# CH569 register map
Vendor: WCH Ltd.; File version: 1.0
Registers are 32-bit, read-write, reset 0x0 unless marked. A register's access mark holds for its fields unless they carry their own. Offsets are from the block's base; [hi:lo] are bit positions; {n}, {i} and the like mark numbered series; 'fields as' and 'values as' point back to an identical list.

## USBHS
Base 0x40009000
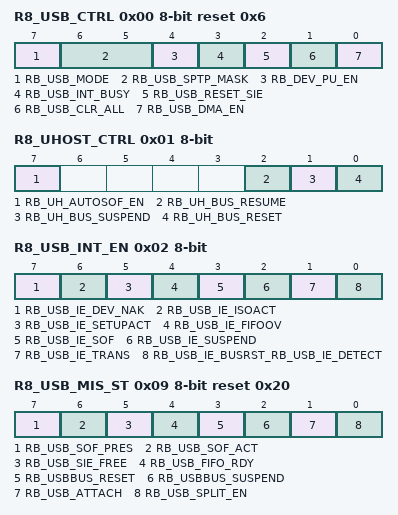
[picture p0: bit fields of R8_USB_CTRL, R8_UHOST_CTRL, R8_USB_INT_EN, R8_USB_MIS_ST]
0x00 R8_USB_CTRL 8-bit reset 0x6 — USB base control
  [7] RB_USB_MODE — enable USB host mode: 0=device mode, 1=host mode
  [6:5] RB_USB_SPTP_MASK — enable USB low speed
  [4] RB_DEV_PU_EN — USB device enable and internal pullup resistance enable
  [3] RB_USB_INT_BUSY — enable automatic responding busy for device mode or automatic pause for host mode during interrupt flag UIF_TRANSFER valid
  [2] RB_USB_RESET_SIE — force reset USB SIE, need software clear
  [1] RB_USB_CLR_ALL — force clear FIFO and count of USB
  [0] RB_USB_DMA_EN — DMA enable and DMA interrupt enable for USB
0x01 R8_UHOST_CTRL 8-bit — USB host control register
  [7] RB_UH_AUTOSOF_EN — Automatically generate sof packet enable control
  [2] RB_UH_BUS_RESUME — USB host suspend state and wake up device
  [1] RB_UH_BUS_SUSPEND — USB host send bus suspend signal
  [0] RB_UH_BUS_RESET — USB host send bus reset signal
0x02 R8_USB_INT_EN 8-bit — USB interrupt enable
  [7] RB_USB_IE_DEV_NAK — enable interrupt for NAK responded for USB device mode
  [6] RB_USB_IE_ISOACT — Synchronous transmission received control token packet interrupt
  [5] RB_USB_IE_SETUPACT — Setup packet end interrupt
  [4] RB_USB_IE_FIFOOV — enable interrupt for FIFO overflow
  [3] RB_USB_IE_SOF — enable interrupt for host SOF timer action for USB host mode
  [2] RB_USB_IE_SUSPEND — enable interrupt for USB suspend or resume event
  [1] RB_USB_IE_TRANS — enable interrupt for USB transfer completion
  [0] RB_USB_IE_BUSRST_RB_USB_IE_DETECT — enable interrupt for USB bus reset event for USB device mode _ enable interrupt for USB device detected event for USB host mode
0x03 R8_USB_DEV_AD 8-bit — USB device address
  [6:0] USB_ADDR_MASK — bit mask for USB device address
0x04 R16_USB_FRAME_NO 16-bit ro — USB frame number register
  [15:0] USB_FRAME_NO — USB frame number
0x06 R8_USB_SUSPEND 8-bit — USB suspend register
  [1] RB_DEV_WAKEUP — Remote wake-up control bit
0x08 R8_USB_SPD_TYPE 8-bit ro — USB actual speed register
  [1:0] RB_USBSPEED_MASK — USB actual speed
0x09 R8_USB_MIS_ST 8-bit ro reset 0x20 — USB miscellaneous status
  [7] RB_USB_SOF_PRES — RO, indicate host SOF timer presage status
  [6] RB_USB_SOF_ACT — RO, indicate host SOF timer action status for USB host
  [5] RB_USB_SIE_FREE — RO, indicate USB SIE free status
  [4] RB_USB_FIFO_RDY — RO, indicate USB receiving FIFO ready status (not empty)
  [3] RB_USBBUS_RESET — RO, indicate USB bus reset status
  [2] RB_USBBUS_SUSPEND — RO, indicate USB suspend status
  [1] RB_USB_ATTACH — RO, indicate device attached status on USB host
  [0] RB_USB_SPLIT_EN — RO,indicate host allow SPLIT packet
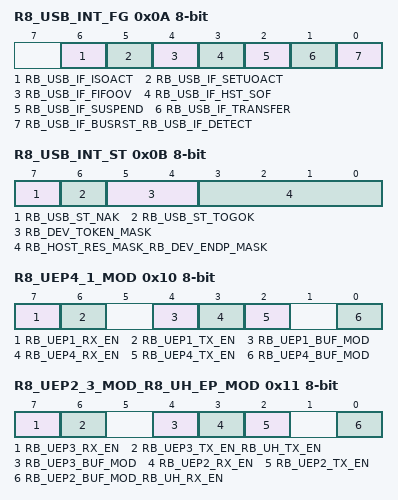
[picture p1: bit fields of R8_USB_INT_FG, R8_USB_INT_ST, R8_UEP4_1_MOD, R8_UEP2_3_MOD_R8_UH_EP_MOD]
0x0A R8_USB_INT_FG 8-bit — USB interrupt flag
  [6] RB_USB_IF_ISOACT — RO, Synchronous transmission received control token packet interrupt flag
  [5] RB_USB_IF_SETUOACT — RO, Setup transaction end interrupt flag
  [4] RB_USB_IF_FIFOOV — FIFO overflow interrupt flag for USB, direct bit address clear or write 1 to clear
  [3] RB_USB_IF_HST_SOF — host SOF timer interrupt flag for USB host, direct bit address clear or write 1 to clear
  [2] RB_USB_IF_SUSPEND — USB suspend or resume event interrupt flag, direct bit address clear or write 1 to clear
  [1] RB_USB_IF_TRANSFER — USB transfer completion interrupt flag, direct bit address clear or write 1 to clear
  [0] RB_USB_IF_BUSRST_RB_USB_IF_DETECT — bus reset event interrupt flag for USB device mode, direct bit address clear or write 1 to clear;device detected event interrupt flag for USB host mode, direct bit address clear or write 1 to clear
0x0B R8_USB_INT_ST 8-bit ro — USB interrupt status
  [7] RB_USB_ST_NAK — RO, indicate current USB transfer is NAK received for USB device mode
  [6] RB_USB_ST_TOGOK — RO, indicate current USB transfer toggle is OK
  [5:4] RB_DEV_TOKEN_MASK — RO, bit mask of current token PID code received for USB device mode
  [3:0] RB_HOST_RES_MASK_RB_DEV_ENDP_MASK — RO, bit mask of current transfer handshake response for USB host mode: 0000=no response, time out from device, others=handshake response PID received;RO, bit mask of current transfer endpoint number for USB device mode
0x0C R6_USB_RX_LEN 16-bit ro — USB receiving length
  [15:0] USB_RX_LEN — length of received bytes
0x10 R8_UEP4_1_MOD 8-bit — endpoint 1(9) 4(8,12) mode
  [7] RB_UEP1_RX_EN — enable USB endpoint 1(9) receiving (OUT)
  [6] RB_UEP1_TX_EN — enable USB endpoint 1(9) transmittal (IN)
  [4] RB_UEP1_BUF_MOD — buffer mode of USB endpoint 1(9)
  [3] RB_UEP4_RX_EN — enable USB endpoint 4(8,12) receiving (OUT)
  [2] RB_UEP4_TX_EN — enable USB endpoint 4(8,12) transmittal (IN)
  [0] RB_UEP4_BUF_MOD — buffer mode of USB endpoint 4(8,12)
0x11 R8_UEP2_3_MOD_R8_UH_EP_MOD 8-bit — endpoint 2(10) 3(11) mode and USB host endpoint mode control register
  [7] RB_UEP3_RX_EN — enable USB endpoint 3(11) receiving (OUT)
  [6] RB_UEP3_TX_EN_RB_UH_TX_EN — enable USB endpoint 3(11) transmittal (IN) and USB host send endpoint (SETUP/OUT) enable
  [4] RB_UEP3_BUF_MOD — buffer mode of USB endpoint 3(11)
  [3] RB_UEP2_RX_EN — enable USB endpoint 2(10) receiving (OUT)
  [2] RB_UEP2_TX_EN — enable USB endpoint 2(10) transmittal (IN)
  [0] RB_UEP2_BUF_MOD_RB_UH_RX_EN — buffer mode of USB endpoint 2(10) and USB host receive endpoint (IN) enable
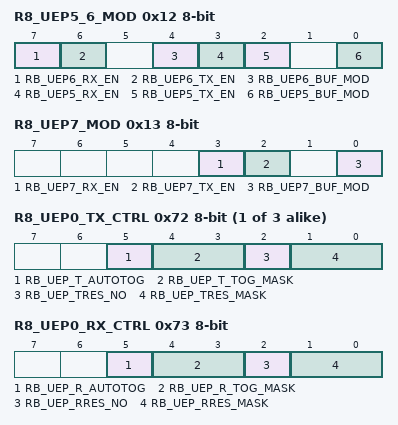
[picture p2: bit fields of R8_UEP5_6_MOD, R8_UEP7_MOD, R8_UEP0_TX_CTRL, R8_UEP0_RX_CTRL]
0x12 R8_UEP5_6_MOD 8-bit — endpoint 5(13) 6(14) mode
  [7] RB_UEP6_RX_EN — enable USB endpoint 6(14) receiving (OUT)
  [6] RB_UEP6_TX_EN — enable USB endpoint 6(14) transmittal (IN)
  [4] RB_UEP6_BUF_MOD — buffer mode of USB endpoint 6(14)
  [3] RB_UEP5_RX_EN — enable USB endpoint 5(13) receiving (OUT)
  [2] RB_UEP5_TX_EN — enable USB endpoint 5(13) transmittal (IN)
  [0] RB_UEP5_BUF_MOD — buffer mode of USB endpoint 5(13)
0x13 R8_UEP7_MOD 8-bit — endpoint 7(15) mode
  [3] RB_UEP7_RX_EN — enable USB endpoint 7(15) receiving (OUT)
  [2] RB_UEP7_TX_EN — enable USB endpoint 7(15) transmittal (IN)
  [0] RB_UEP7_BUF_MOD — buffer mode of USB endpoint 7(15)
0x14 R32_UEP0_RT_DMA — endpoint 0 DMA buffer address
  [16:0] UEP0_RT_DMA
0x18 R32_UEP1_RX_DMA — endpoint 1 DMA buffer address
  [16:0] UEP1_RX_DMA
0x1C R32_UEP2_RX_DMA_R32_UH_RX_DMA — endpoint 2 DMA buffer address _ host rx endpoint buffer start address
  [16:0] UEP2_RX_DMA_UH_RX_DMA
0x20 R32_UEP3_RX_DMA — endpoint 3 DMA buffer address;host tx endpoint buffer high address
  [16:0] UEP3_RX_DMA — endpoint 3 DMA buffer address
{0x14+4i} R32_UEP{i}_RX_DMA (i=4..7) — endpoint {i} DMA buffer address
  [16:0] UEP{i}_RX_DMA
0x34 R32_UEP1_TX_DMA — endpoint 1 DMA TX buffer address
  [16:0] UEP1_TX_DMA
0x38 R32_UEP2_TX_DMA — endpoint 2 DMA TX buffer address
  [16:0] UEP2_TX_DMA
0x3C R32_UEP3_TX_DMA_R32_UH_TX_DMA — endpoint 3 DMA TX buffer address and host tx endpoint buffer start address
  [16:0] UEP3_TX_DMA_UH_TX_DMA
0x40 R32_UEP4_TX_DMA — endpoint 4 DMA TX buffer address
  [16:0] UEP4_TX_DMA
0x44 R32_UEP5_TX_DMA — endpoint 5 DMA TX buffer address
  [16:0] UEP5_TX_DMA
0x48 R32_UEP6_TX_DMA — endpoint 4 DMA TX buffer address
  [16:0] UEP6_TX_DMA — endpoint 6 DMA TX buffer address
0x4C R32_UEP7_TX_DMA — endpoint 7 DMA TX buffer address
  [16:0] UEP7_TX_DMA
0x50 R16_UEP0_MAX_LEN 16-bit — endpoint 0 receive max length
  [15:0] UEP0_MAX_LEN
0x54 R16_UEP1_MAX_LEN 16-bit — endpoint 1 receive max length
  [15:0] UEP1_MAX_LEN
0x58 R16_UEP2_MAX_LEN_R16_UH_MAX_LEN 16-bit — endpoint 2 receive max length and USB host receive max packet length register
  [15:0] UEP2_MAX_LEN_UH_MAX_LEN
{0x50+4i} R16_UEP{i}_MAX_LEN 16-bit (i=3..7) — endpoint {i} receive max length
  [15:0] UEP{i}_MAX_LEN
0x70 R16_UEP0_T_LEN 16-bit — endpoint 0 transmittal length
  [15:0] UEP0_T_LEN
{0x72+4i} R8_UEP{i}_TX_CTRL 8-bit (i=0..2) — endpoint {i} tx control
  [5] RB_UEP_T_AUTOTOG — enable automatic toggle after successful transfer completion on endpoint 0
  [4:3] RB_UEP_T_TOG_MASK — prepared data toggle flag of USB endpoint X transmittal
  [2] RB_UEP_TRES_NO — expected no response
  [1:0] RB_UEP_TRES_MASK — bit mask of handshake response type for USB endpoint X transmittal (IN)
0x73 R8_UEP0_RX_CTRL 8-bit — endpoint 0 rx control
  [5] RB_UEP_R_AUTOTOG — enable automatic toggle after successful transfer completion on endpoint
  [4:3] RB_UEP_R_TOG_MASK — expected data toggle flag of USB endpoint X receiving
  [2] RB_UEP_RRES_NO — prepared no response
  [1:0] RB_UEP_RRES_MASK — bit mask of handshake response type for USB endpoint X receiving (OUT)
0x74 R16_UEP1_T_LEN 16-bit — endpoint 1 transmittal length
  [15:0] UEP1_T_LEN
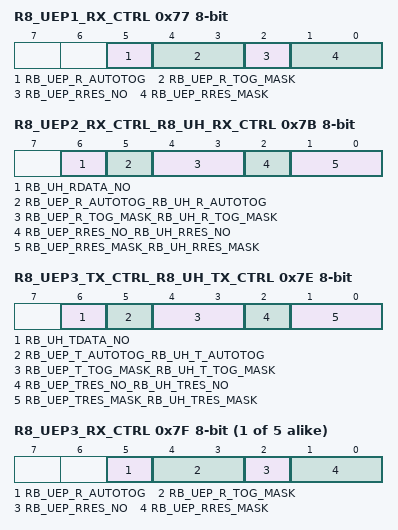
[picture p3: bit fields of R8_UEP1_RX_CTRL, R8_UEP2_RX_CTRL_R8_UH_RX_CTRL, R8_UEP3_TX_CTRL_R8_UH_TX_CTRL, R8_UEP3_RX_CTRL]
0x77 R8_UEP1_RX_CTRL 8-bit — endpoint 1 rx control
  fields as R8_UEP0_RX_CTRL
0x78 R16_UEP2_T_LEN_R16_UH_EP_PID 16-bit — endpoint 2 transmittal length and Set usb host token register
  [7:4] RB_UH_TOKEN_MASK — The token PID packet identification of this USB transfer transaction
  [3:0] RB_UH_EPNUM_MASK — The endpoint number of the target of this operation
  [15:0] UEP2_T_LEN — endpoint 2 transmittal length
0x7B R8_UEP2_RX_CTRL_R8_UH_RX_CTRL 8-bit — endpoint 2 rx control and USb host receive endpoint control register
  [6] RB_UH_RDATA_NO — expect no data packet, for high speed hub in host mode
  [5] RB_UEP_R_AUTOTOG_RB_UH_R_AUTOTOG — enable automatic toggle after successful transfer completion on endpoint and enable automatic toggle after successful receiver completion
  [4:3] RB_UEP_R_TOG_MASK_RB_UH_R_TOG_MASK — expected data toggle flag of USB endpoint X receiving and expected data toggle flag of host receiving (IN)
  [2] RB_UEP_RRES_NO_RB_UH_RRES_NO — Prepared no response and Response control bit of host receiver
  [1:0] RB_UEP_RRES_MASK_RB_UH_RRES_MASK — bit mask of handshake response type for USB endpoint X receiving (OUT) and Host reeiver response control bit
0x7C R16_UEP3_T_LEN_R16_UH_TX_LEN 16-bit — endpoint 3 transmittal length and host transmittal endpoint transmittal length
  [15:0] UEP3_T_LEN_UH_TX_LEN
0x7E R8_UEP3_TX_CTRL_R8_UH_TX_CTRL 8-bit — endpoint 3 tx control and host transmittal endpoint control
  [6] RB_UH_TDATA_NO — prepared no data packet, for high speed hub in host mode
  [5] RB_UEP_T_AUTOTOG_RB_UH_T_AUTOTOG — enable automatic toggle after successful transfer completion on endpoint 0 and enable automatic toggle after successful transfer completion
  [4:3] RB_UEP_T_TOG_MASK_RB_UH_T_TOG_MASK — prepared data toggle flag of USB endpoint X transmittal and prepared data toggle flag of host transmittal (SETUP/OUT)
  [2] RB_UEP_TRES_NO_RB_UH_TRES_NO — expected no response and expected no response, 1=enable, 0=disable, for non-zero endpoint isochronous transactions
  [1:0] RB_UEP_TRES_MASK_RB_UH_TRES_MASK — bit mask of handshake response type for USB endpoint X transmittal (IN) and expected handshake response type for host transmittal (SETUP/OUT)
{0x73+4i} R8_UEP{i}_RX_CTRL 8-bit (i=3..7) — endpoint {i} rx control
  fields as R8_UEP0_RX_CTRL
0x80 R16_UEP4_T_LEN_R16_UH_SPLIT_DATA 16-bit — endpoint 4 transmittal length and USB host Tx SPLIT packet data
  [15:0] UEP4_T_LEN_UH_SPLIT_DATA
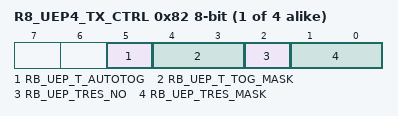
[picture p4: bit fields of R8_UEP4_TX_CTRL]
{0x72+4i} R8_UEP{i}_TX_CTRL 8-bit (i=4..7) — endpoint {i} tx control
  fields as R8_UEP0_TX_CTRL
{0x70+4i} R16_UEP{i}_T_LEN 16-bit (i=5..7) — endpoint {i} transmittal length
  [15:0] UEP{i}_T_LEN
